# RZT2H register map
Vendor: Renesas Electronics Corporation; Series: RZT; File version: 1.00.00
CPU: other r0p0, little endian, MPU, no FPU, VTOR, 4 interrupt priority bits, 624 interrupts
Registers are 32-bit, read-write, reset 0x0 unless marked. A register's access mark holds for its fields unless they carry their own. Offsets are from the block's base; [hi:lo] are bit positions; {n}, {i} and the like mark numbered series.

## DDRSS
Base 0x80300000
0x00 DDR_MEMC_DENALI_CTL_00
  [0] start
0x100 DDR_MEMC_DENALI_CTL_64
  [13:8] BSTLEN
0x19C DDR_MEMC_DENALI_CTL_103
  [0] PWRUP_SREFRESH_EXIT
0x278 DDR_MEMC_DENALI_CTL_158
  [21:16] LPI_WAKEUP_EN
0x280 DDR_MEMC_DENALI_CTL_160
  [27:24] LP_AUTO_ENTRY_EN
0x29C DDR_MEMC_DENALI_CTL_167
  [8] PCPCS_PD_EN
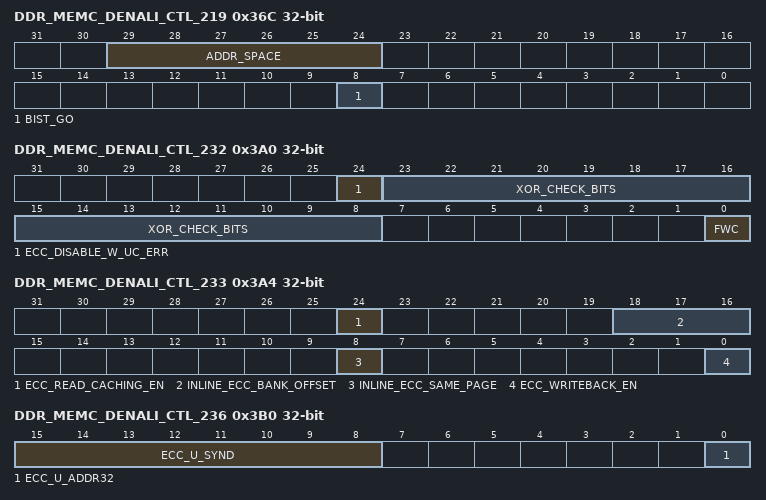
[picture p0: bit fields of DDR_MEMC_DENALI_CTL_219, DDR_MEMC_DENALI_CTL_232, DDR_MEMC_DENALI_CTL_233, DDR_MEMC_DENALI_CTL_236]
0x36C DDR_MEMC_DENALI_CTL_219
  [29:24] ADDR_SPACE, [8] BIST_GO
0x370 DDR_MEMC_DENALI_CTL_220
  [0] BIST_DATA_CHECK
0x374 DDR_MEMC_DENALI_CTL_221
  [31:0] BIST_START_ADDRESS
0x378 DDR_MEMC_DENALI_CTL_222
  [0] BIST_START_ADDRESS32
0x384 DDR_MEMC_DENALI_CTL_225
  [2:0] BIST_TEST_MODE
{0x0+4i} DDR_MEMC_DENALI_CTL_{i} (i=226..229)
  [31:0] BIST_DATA_PATTERN{i-226}
0x39C DDR_MEMC_DENALI_CTL_231
  [25:24] ECC_ENABLE
0x3A0 DDR_MEMC_DENALI_CTL_232
  [24] ECC_DISABLE_W_UC_ERR, [23:8] XOR_CHECK_BITS, [0] FWC
0x3A4 DDR_MEMC_DENALI_CTL_233
  [24] ECC_READ_CACHING_EN, [18:16] INLINE_ECC_BANK_OFFSET, [8] INLINE_ECC_SAME_PAGE, [0] ECC_WRITEBACK_EN
0x3A8 DDR_MEMC_DENALI_CTL_234
  [0] ECC_WRITE_COMBINING_EN
0x3AC DDR_MEMC_DENALI_CTL_235 ro
  [31:0] ECC_U_ADDR
0x3B0 DDR_MEMC_DENALI_CTL_236 ro
  [15:8] ECC_U_SYND, [0] ECC_U_ADDR32
0x3B4 DDR_MEMC_DENALI_CTL_237 ro
  [31:0] ECC_U_DATA0
0x3B8 DDR_MEMC_DENALI_CTL_238 ro
  [31:0] ECC_U_DATA1
0x3BC DDR_MEMC_DENALI_CTL_239 ro
  [31:0] ECC_C_ADDR
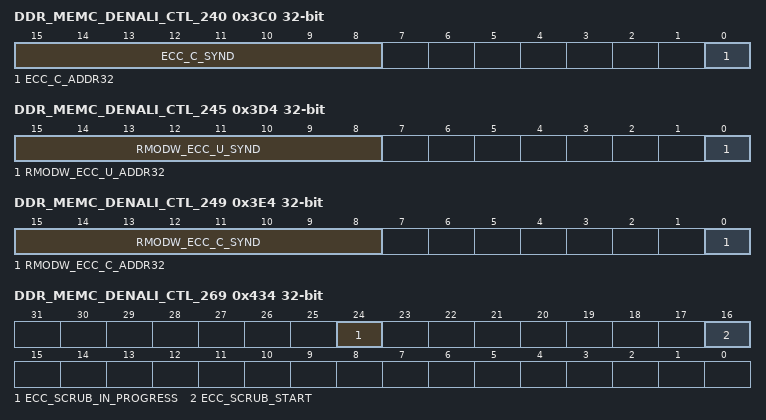
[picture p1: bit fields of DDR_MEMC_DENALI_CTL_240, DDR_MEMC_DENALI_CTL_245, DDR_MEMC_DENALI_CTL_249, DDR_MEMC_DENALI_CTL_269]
0x3C0 DDR_MEMC_DENALI_CTL_240 ro
  [15:8] ECC_C_SYND, [0] ECC_C_ADDR32
0x3C4 DDR_MEMC_DENALI_CTL_241 ro
  [31:0] ECC_C_DATA0
0x3C8 DDR_MEMC_DENALI_CTL_242 ro
  [31:0] ECC_C_DATA1
0x3D0 DDR_MEMC_DENALI_CTL_244 ro
  [31:0] RMODW_ECC_U_ADDR
0x3D4 DDR_MEMC_DENALI_CTL_245 ro
  [15:8] RMODW_ECC_U_SYND, [0] RMODW_ECC_U_ADDR32
0x3D8 DDR_MEMC_DENALI_CTL_246 ro
  [31:0] RMODW_ECC_U_DATA0
0x3DC DDR_MEMC_DENALI_CTL_247 ro
  [31:0] RMODW_ECC_U_DATA1
0x3E0 DDR_MEMC_DENALI_CTL_248 ro
  [31:0] RMODW_ECC_C_ADDR
0x3E4 DDR_MEMC_DENALI_CTL_249 ro
  [15:8] RMODW_ECC_C_SYND, [0] RMODW_ECC_C_ADDR32
0x3E8 DDR_MEMC_DENALI_CTL_250 ro
  [31:0] RMODW_ECC_C_DATA0
0x3EC DDR_MEMC_DENALI_CTL_251 ro
  [31:0] RMODW_ECC_C_DATA1
0x434 DDR_MEMC_DENALI_CTL_269
  [24] ECC_SCRUB_IN_PROGRESS ro, [16] ECC_SCRUB_START wo
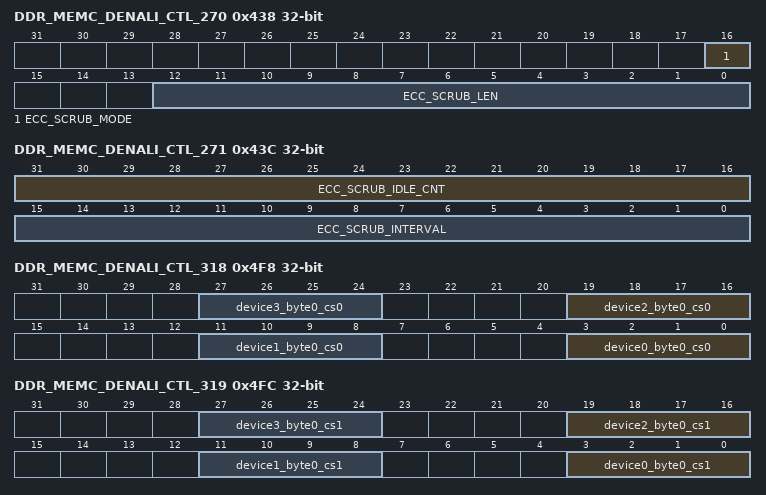
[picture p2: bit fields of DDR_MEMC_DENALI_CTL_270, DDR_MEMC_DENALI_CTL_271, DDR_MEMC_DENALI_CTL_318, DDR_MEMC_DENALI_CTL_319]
0x438 DDR_MEMC_DENALI_CTL_270
  [16] ECC_SCRUB_MODE, [12:0] ECC_SCRUB_LEN
0x43C DDR_MEMC_DENALI_CTL_271
  [31:16] ECC_SCRUB_IDLE_CNT, [15:0] ECC_SCRUB_INTERVAL
0x440 DDR_MEMC_DENALI_CTL_272
  [31:0] ECC_SCRUB_START_ADDR
0x444 DDR_MEMC_DENALI_CTL_273
  [0] ECC_SCRUB_START_ADDR32
0x448 DDR_MEMC_DENALI_CTL_274
  [31:0] ECC_SCRUB_END_ADDR
0x44C DDR_MEMC_DENALI_CTL_275
  [0] ECC_SCRUB_END_ADDR32
0x4C0 DDR_MEMC_DENALI_CTL_304
  [31:16] CS_VAL_UPPER_0
0x4C8 DDR_MEMC_DENALI_CTL_306
  [31:16] CS_VAL_UPPER_1
0x4E0 DDR_MEMC_DENALI_CTL_312
  [25:24] CS_MAP
0x4E4 DDR_MEMC_DENALI_CTL_313
  [0] MEM_DP_REDUCTION
0x4F8 DDR_MEMC_DENALI_CTL_318
  [8n+3:8n] device{n}_byte0_cs0 (n=0..3)
0x4FC DDR_MEMC_DENALI_CTL_319
  [8n+3:8n] device{n}_byte0_cs1 (n=0..3)
0x518 DDR_MEMC_DENALI_CTL_326 ro
  [31:0] INT_STATUS_MASTER
0x51C DDR_MEMC_DENALI_CTL_327 wo
  [31:0] INT_MASK_MASTER
0x520 DDR_MEMC_DENALI_CTL_328 ro
  [31:0] INT_STATUS_TIMEOUT
0x524 DDR_MEMC_DENALI_CTL_329 ro
  [31:0] INT_STATUS_ECC
0x528 DDR_MEMC_DENALI_CTL_330 ro
  [15:0] INT_STATUS_LOWPOWER
0x530 DDR_MEMC_DENALI_CTL_332 ro
  [31:0] INT_STATUS_TRAINING
0x534 DDR_MEMC_DENALI_CTL_333 ro
  [31:0] INT_STATUS_USERIF
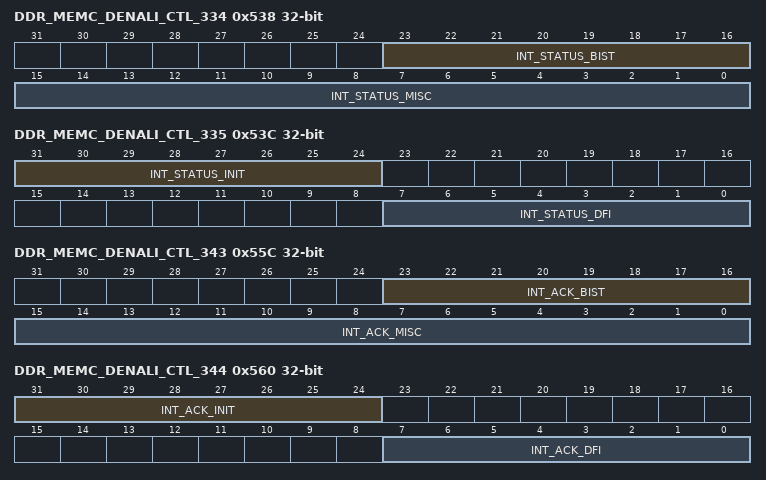
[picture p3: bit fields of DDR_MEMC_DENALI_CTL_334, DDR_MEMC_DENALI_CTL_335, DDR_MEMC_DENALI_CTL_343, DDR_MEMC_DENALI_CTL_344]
0x538 DDR_MEMC_DENALI_CTL_334 ro
  [23:16] INT_STATUS_BIST, [15:0] INT_STATUS_MISC
0x53C DDR_MEMC_DENALI_CTL_335 ro
  [31:24] INT_STATUS_INIT, [7:0] INT_STATUS_DFI
0x540 DDR_MEMC_DENALI_CTL_336 ro
  [7:0] INT_STATUS_MODE
0x544 DDR_MEMC_DENALI_CTL_337 wo
  [31:0] INT_ACK_TIMEOUT
0x548 DDR_MEMC_DENALI_CTL_338 wo
  [31:0] INT_ACK_ECC
0x54C DDR_MEMC_DENALI_CTL_339 wo
  [15:0] INT_ACK_LOWPOWER
0x554 DDR_MEMC_DENALI_CTL_341 wo
  [31:0] INT_ACK_TRAINING
0x558 DDR_MEMC_DENALI_CTL_342 wo
  [31:0] INT_ACK_USERIF
0x55C DDR_MEMC_DENALI_CTL_343 wo
  [23:16] INT_ACK_BIST, [15:0] INT_ACK_MISC
0x560 DDR_MEMC_DENALI_CTL_344 wo
  [31:24] INT_ACK_INIT, [7:0] INT_ACK_DFI
0x564 DDR_MEMC_DENALI_CTL_345 wo
  [7:0] INT_ACK_MODE
0x568 DDR_MEMC_DENALI_CTL_346
  [31:0] INT_MASK_TIMEOUT
0x56C DDR_MEMC_DENALI_CTL_347
  [31:0] INT_MASK_ECC
0x570 DDR_MEMC_DENALI_CTL_348
  [15:0] INT_MASK_LOWPOWER
0x578 DDR_MEMC_DENALI_CTL_350
  [31:0] INT_MASK_TRAINING
0x57C DDR_MEMC_DENALI_CTL_351
  [31:0] INT_MASK_USERIF
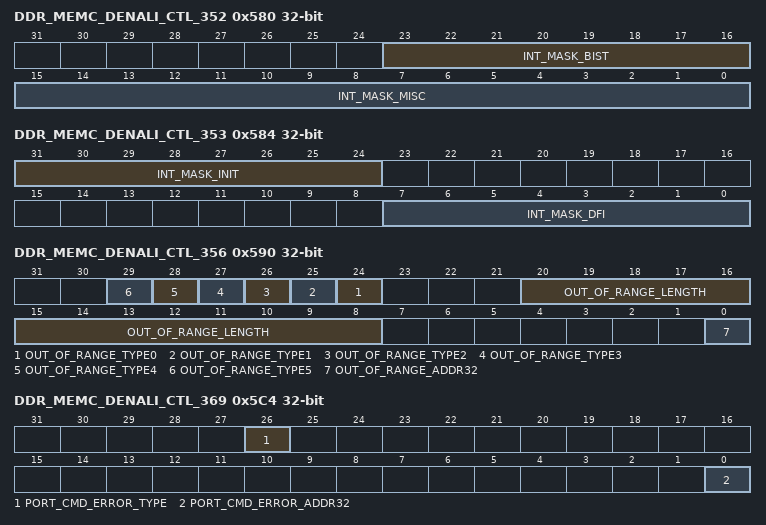
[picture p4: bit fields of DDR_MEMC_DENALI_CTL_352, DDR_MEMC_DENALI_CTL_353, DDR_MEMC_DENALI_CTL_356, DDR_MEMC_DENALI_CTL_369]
0x580 DDR_MEMC_DENALI_CTL_352
  [23:16] INT_MASK_BIST, [15:0] INT_MASK_MISC
0x584 DDR_MEMC_DENALI_CTL_353
  [31:24] INT_MASK_INIT, [7:0] INT_MASK_DFI
0x588 DDR_MEMC_DENALI_CTL_354
  [7:0] INT_MASK_MODE
0x58C DDR_MEMC_DENALI_CTL_355 ro
  [31:0] OUT_OF_RANGE_ADDR
0x590 DDR_MEMC_DENALI_CTL_356 ro
  [n+24] OUT_OF_RANGE_TYPE{n} (n=0..5), [20:8] OUT_OF_RANGE_LENGTH, [0] OUT_OF_RANGE_ADDR32
0x5C0 DDR_MEMC_DENALI_CTL_368 ro
  [31:0] PORT_CMD_ERROR_ADDR
0x5C4 DDR_MEMC_DENALI_CTL_369 ro
  [26] PORT_CMD_ERROR_TYPE, [0] PORT_CMD_ERROR_ADDR32
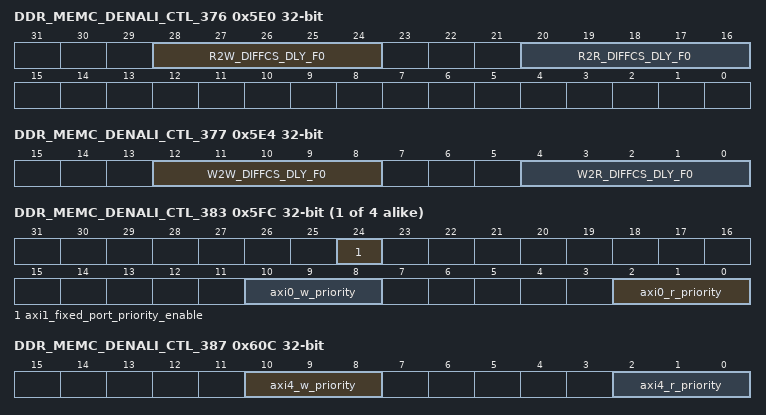
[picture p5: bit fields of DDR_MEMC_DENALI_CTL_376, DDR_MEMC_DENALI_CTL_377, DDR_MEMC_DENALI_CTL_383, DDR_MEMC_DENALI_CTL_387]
0x5E0 DDR_MEMC_DENALI_CTL_376
  [28:24] R2W_DIFFCS_DLY_F0, [20:16] R2R_DIFFCS_DLY_F0
0x5E4 DDR_MEMC_DENALI_CTL_377
  [12:8] W2W_DIFFCS_DLY_F0, [4:0] W2R_DIFFCS_DLY_F0
0x5F8 DDR_MEMC_DENALI_CTL_382
  [24] axi0_fixed_port_priority_enable
{0x0+4i} DDR_MEMC_DENALI_CTL_{i} (i=383..386)
  [24] axi{i-382}_fixed_port_priority_enable, [10:8] axi{i-383}_w_priority, [2:0] axi{i-383}_r_priority
0x60C DDR_MEMC_DENALI_CTL_387
  [10:8] axi4_w_priority, [2:0] axi4_r_priority
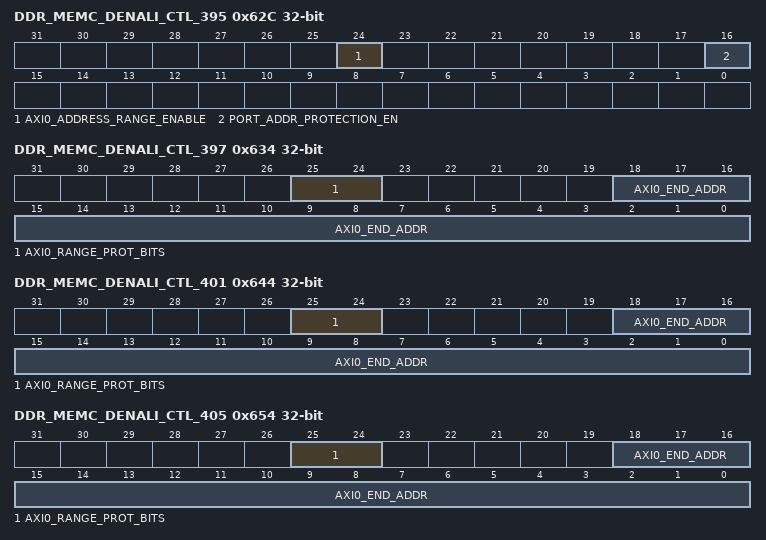
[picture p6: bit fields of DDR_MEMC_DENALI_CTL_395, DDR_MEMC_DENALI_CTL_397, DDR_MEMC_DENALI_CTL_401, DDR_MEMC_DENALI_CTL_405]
0x62C DDR_MEMC_DENALI_CTL_395
  [24] AXI0_ADDRESS_RANGE_ENABLE, [16] PORT_ADDR_PROTECTION_EN
0x630 DDR_MEMC_DENALI_CTL_396
  [18:0] AXI0_START_ADDR
0x634 DDR_MEMC_DENALI_CTL_397
  [25:24] AXI0_RANGE_PROT_BITS, [18:0] AXI0_END_ADDR
0x640 DDR_MEMC_DENALI_CTL_400
  [18:0] AXI0_START_ADDR
0x644 DDR_MEMC_DENALI_CTL_401
  [25:24] AXI0_RANGE_PROT_BITS, [18:0] AXI0_END_ADDR
0x650 DDR_MEMC_DENALI_CTL_404
  [18:0] AXI0_START_ADDR
0x654 DDR_MEMC_DENALI_CTL_405
  [25:24] AXI0_RANGE_PROT_BITS, [18:0] AXI0_END_ADDR
0x660 DDR_MEMC_DENALI_CTL_408
  [18:0] AXI0_START_ADDR
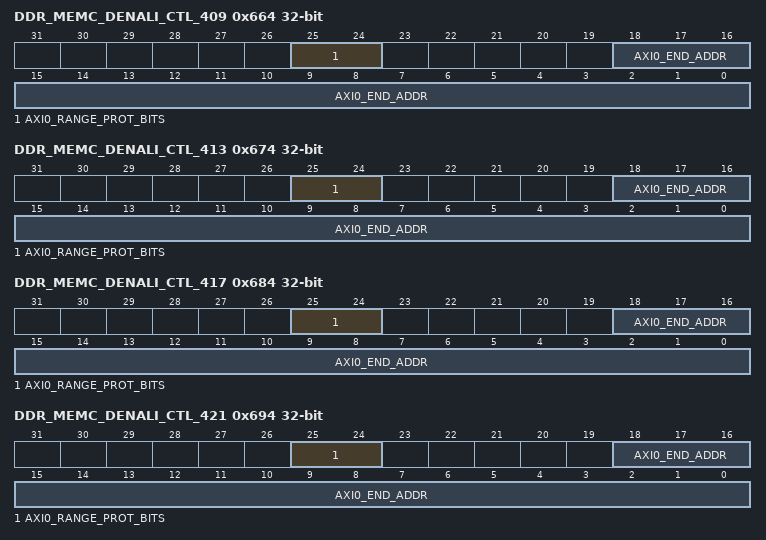
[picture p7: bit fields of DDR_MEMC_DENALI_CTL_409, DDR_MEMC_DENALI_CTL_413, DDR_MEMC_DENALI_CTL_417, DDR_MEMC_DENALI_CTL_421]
0x664 DDR_MEMC_DENALI_CTL_409
  [25:24] AXI0_RANGE_PROT_BITS, [18:0] AXI0_END_ADDR
0x670 DDR_MEMC_DENALI_CTL_412
  [18:0] AXI0_START_ADDR
0x674 DDR_MEMC_DENALI_CTL_413
  [25:24] AXI0_RANGE_PROT_BITS, [18:0] AXI0_END_ADDR
0x680 DDR_MEMC_DENALI_CTL_416
  [18:0] AXI0_START_ADDR
0x684 DDR_MEMC_DENALI_CTL_417
  [25:24] AXI0_RANGE_PROT_BITS, [18:0] AXI0_END_ADDR
0x690 DDR_MEMC_DENALI_CTL_420
  [18:0] AXI0_START_ADDR
0x694 DDR_MEMC_DENALI_CTL_421
  [25:24] AXI0_RANGE_PROT_BITS, [18:0] AXI0_END_ADDR
0x6A0 DDR_MEMC_DENALI_CTL_424
  [18:0] AXI0_START_ADDR
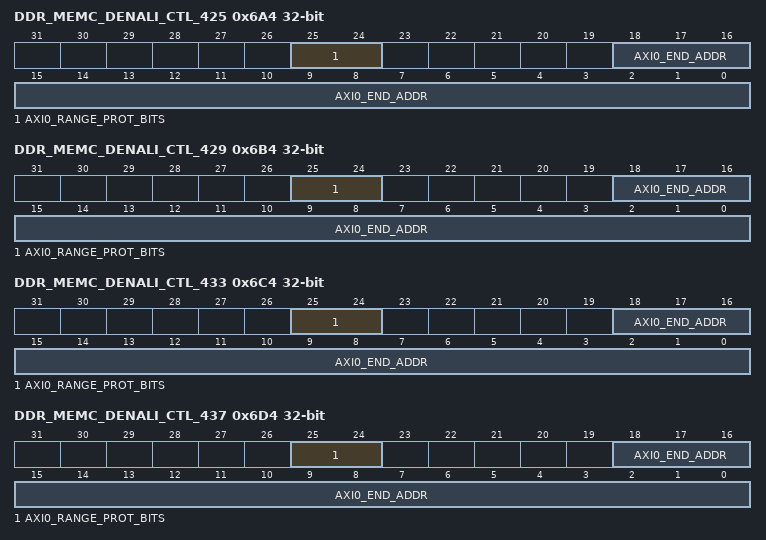
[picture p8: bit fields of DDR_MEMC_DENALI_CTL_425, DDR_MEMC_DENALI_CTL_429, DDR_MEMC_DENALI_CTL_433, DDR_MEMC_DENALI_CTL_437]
0x6A4 DDR_MEMC_DENALI_CTL_425
  [25:24] AXI0_RANGE_PROT_BITS, [18:0] AXI0_END_ADDR
0x6B0 DDR_MEMC_DENALI_CTL_428
  [18:0] AXI0_START_ADDR
0x6B4 DDR_MEMC_DENALI_CTL_429
  [25:24] AXI0_RANGE_PROT_BITS, [18:0] AXI0_END_ADDR
0x6C0 DDR_MEMC_DENALI_CTL_432
  [18:0] AXI0_START_ADDR
0x6C4 DDR_MEMC_DENALI_CTL_433
  [25:24] AXI0_RANGE_PROT_BITS, [18:0] AXI0_END_ADDR
0x6D0 DDR_MEMC_DENALI_CTL_436
  [18:0] AXI0_START_ADDR
0x6D4 DDR_MEMC_DENALI_CTL_437
  [25:24] AXI0_RANGE_PROT_BITS, [18:0] AXI0_END_ADDR
0x6E0 DDR_MEMC_DENALI_CTL_440
  [18:0] AXI0_START_ADDR
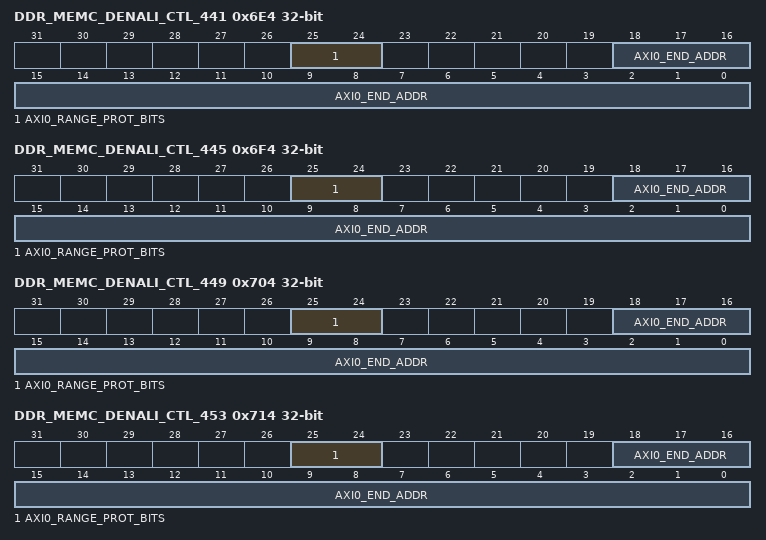
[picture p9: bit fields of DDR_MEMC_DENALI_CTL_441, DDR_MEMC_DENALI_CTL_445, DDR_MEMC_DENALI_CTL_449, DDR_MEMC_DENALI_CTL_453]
0x6E4 DDR_MEMC_DENALI_CTL_441
  [25:24] AXI0_RANGE_PROT_BITS, [18:0] AXI0_END_ADDR
0x6F0 DDR_MEMC_DENALI_CTL_444
  [18:0] AXI0_START_ADDR
0x6F4 DDR_MEMC_DENALI_CTL_445
  [25:24] AXI0_RANGE_PROT_BITS, [18:0] AXI0_END_ADDR
0x700 DDR_MEMC_DENALI_CTL_448
  [18:0] AXI0_START_ADDR
0x704 DDR_MEMC_DENALI_CTL_449
  [25:24] AXI0_RANGE_PROT_BITS, [18:0] AXI0_END_ADDR
0x710 DDR_MEMC_DENALI_CTL_452
  [18:0] AXI0_START_ADDR
0x714 DDR_MEMC_DENALI_CTL_453
  [25:24] AXI0_RANGE_PROT_BITS, [18:0] AXI0_END_ADDR
0x720 DDR_MEMC_DENALI_CTL_456
  [18:0] AXI0_START_ADDR
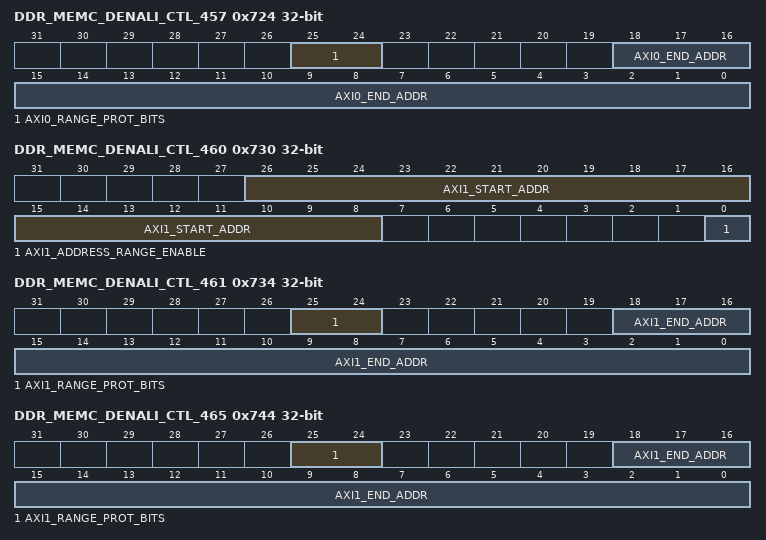
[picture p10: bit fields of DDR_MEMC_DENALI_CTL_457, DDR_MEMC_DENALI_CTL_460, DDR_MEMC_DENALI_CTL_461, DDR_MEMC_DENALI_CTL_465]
0x724 DDR_MEMC_DENALI_CTL_457
  [25:24] AXI0_RANGE_PROT_BITS, [18:0] AXI0_END_ADDR
0x730 DDR_MEMC_DENALI_CTL_460
  [26:8] AXI1_START_ADDR, [0] AXI1_ADDRESS_RANGE_ENABLE
0x734 DDR_MEMC_DENALI_CTL_461
  [25:24] AXI1_RANGE_PROT_BITS, [18:0] AXI1_END_ADDR
0x740 DDR_MEMC_DENALI_CTL_464
  [18:0] AXI1_START_ADDR
0x744 DDR_MEMC_DENALI_CTL_465
  [25:24] AXI1_RANGE_PROT_BITS, [18:0] AXI1_END_ADDR
0x750 DDR_MEMC_DENALI_CTL_468
  [18:0] AXI1_START_ADDR
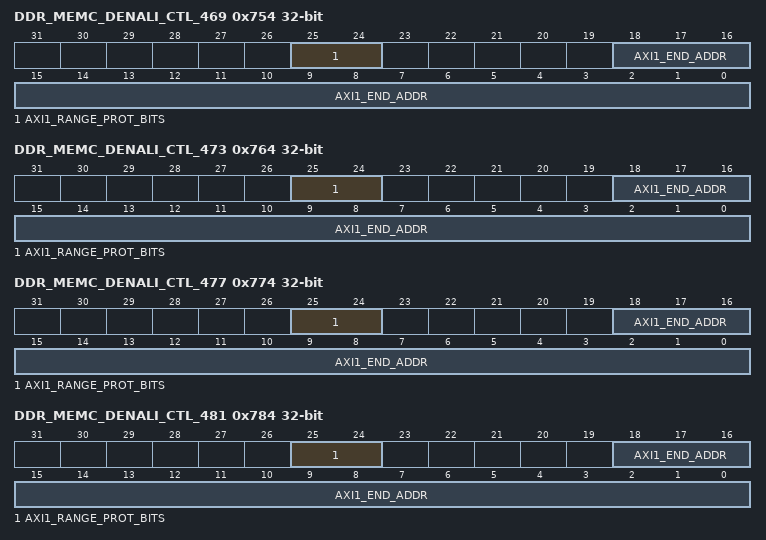
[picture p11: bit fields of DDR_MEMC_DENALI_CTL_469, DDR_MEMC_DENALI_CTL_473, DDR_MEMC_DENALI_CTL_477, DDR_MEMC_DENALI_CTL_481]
0x754 DDR_MEMC_DENALI_CTL_469
  [25:24] AXI1_RANGE_PROT_BITS, [18:0] AXI1_END_ADDR
0x760 DDR_MEMC_DENALI_CTL_472
  [18:0] AXI1_START_ADDR
0x764 DDR_MEMC_DENALI_CTL_473
  [25:24] AXI1_RANGE_PROT_BITS, [18:0] AXI1_END_ADDR
0x770 DDR_MEMC_DENALI_CTL_476
  [18:0] AXI1_START_ADDR
0x774 DDR_MEMC_DENALI_CTL_477
  [25:24] AXI1_RANGE_PROT_BITS, [18:0] AXI1_END_ADDR
0x780 DDR_MEMC_DENALI_CTL_480
  [18:0] AXI1_START_ADDR
0x784 DDR_MEMC_DENALI_CTL_481
  [25:24] AXI1_RANGE_PROT_BITS, [18:0] AXI1_END_ADDR
0x790 DDR_MEMC_DENALI_CTL_484
  [18:0] AXI1_START_ADDR
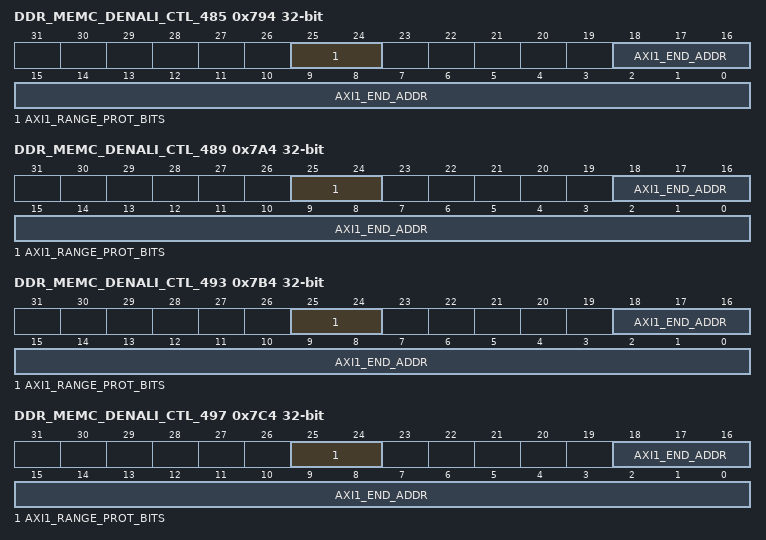
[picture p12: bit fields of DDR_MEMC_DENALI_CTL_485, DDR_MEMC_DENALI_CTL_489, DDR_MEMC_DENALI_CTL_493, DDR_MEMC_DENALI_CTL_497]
0x794 DDR_MEMC_DENALI_CTL_485
  [25:24] AXI1_RANGE_PROT_BITS, [18:0] AXI1_END_ADDR
0x7A0 DDR_MEMC_DENALI_CTL_488
  [18:0] AXI1_START_ADDR
0x7A4 DDR_MEMC_DENALI_CTL_489
  [25:24] AXI1_RANGE_PROT_BITS, [18:0] AXI1_END_ADDR
0x7B0 DDR_MEMC_DENALI_CTL_492
  [18:0] AXI1_START_ADDR
0x7B4 DDR_MEMC_DENALI_CTL_493
  [25:24] AXI1_RANGE_PROT_BITS, [18:0] AXI1_END_ADDR
0x7C0 DDR_MEMC_DENALI_CTL_496
  [18:0] AXI1_START_ADDR
0x7C4 DDR_MEMC_DENALI_CTL_497
  [25:24] AXI1_RANGE_PROT_BITS, [18:0] AXI1_END_ADDR
0x7D0 DDR_MEMC_DENALI_CTL_500
  [18:0] AXI1_START_ADDR
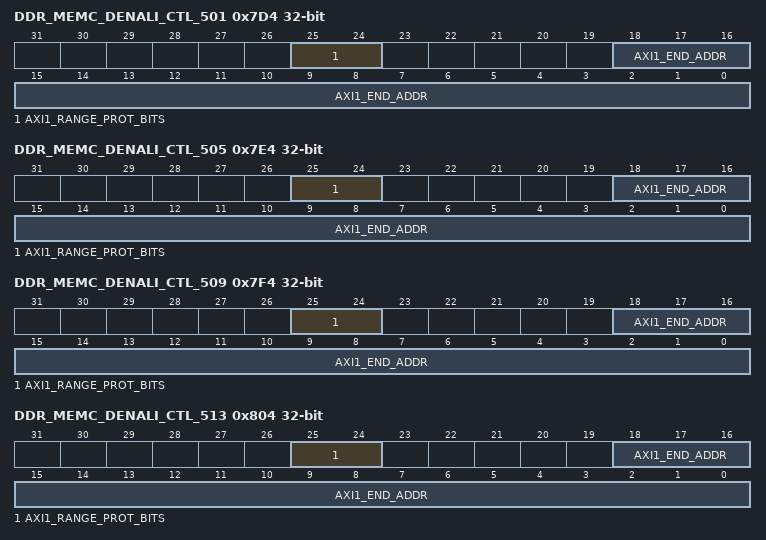
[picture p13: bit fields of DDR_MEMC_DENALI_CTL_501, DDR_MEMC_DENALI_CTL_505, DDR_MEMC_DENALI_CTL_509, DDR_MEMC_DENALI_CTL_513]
0x7D4 DDR_MEMC_DENALI_CTL_501
  [25:24] AXI1_RANGE_PROT_BITS, [18:0] AXI1_END_ADDR
0x7E0 DDR_MEMC_DENALI_CTL_504
  [18:0] AXI1_START_ADDR
0x7E4 DDR_MEMC_DENALI_CTL_505
  [25:24] AXI1_RANGE_PROT_BITS, [18:0] AXI1_END_ADDR
0x7F0 DDR_MEMC_DENALI_CTL_508
  [18:0] AXI1_START_ADDR
0x7F4 DDR_MEMC_DENALI_CTL_509
  [25:24] AXI1_RANGE_PROT_BITS, [18:0] AXI1_END_ADDR
0x800 DDR_MEMC_DENALI_CTL_512
  [18:0] AXI1_START_ADDR
0x804 DDR_MEMC_DENALI_CTL_513
  [25:24] AXI1_RANGE_PROT_BITS, [18:0] AXI1_END_ADDR
0x810 DDR_MEMC_DENALI_CTL_516
  [18:0] AXI1_START_ADDR
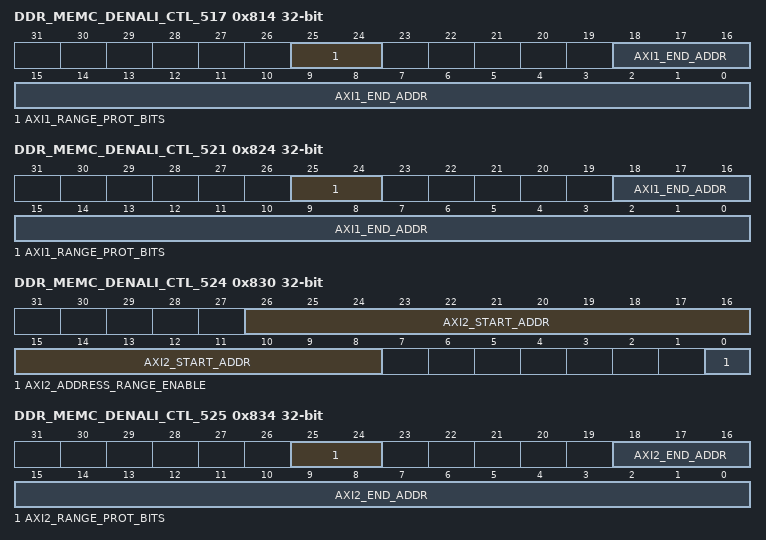
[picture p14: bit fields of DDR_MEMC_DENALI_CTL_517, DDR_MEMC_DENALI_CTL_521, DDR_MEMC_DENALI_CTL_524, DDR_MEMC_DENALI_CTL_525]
0x814 DDR_MEMC_DENALI_CTL_517
  [25:24] AXI1_RANGE_PROT_BITS, [18:0] AXI1_END_ADDR
0x820 DDR_MEMC_DENALI_CTL_520
  [18:0] AXI1_START_ADDR
0x824 DDR_MEMC_DENALI_CTL_521
  [25:24] AXI1_RANGE_PROT_BITS, [18:0] AXI1_END_ADDR
0x830 DDR_MEMC_DENALI_CTL_524
  [26:8] AXI2_START_ADDR, [0] AXI2_ADDRESS_RANGE_ENABLE
0x834 DDR_MEMC_DENALI_CTL_525
  [25:24] AXI2_RANGE_PROT_BITS, [18:0] AXI2_END_ADDR
0x840 DDR_MEMC_DENALI_CTL_528
  [18:0] AXI2_START_ADDR
0x844 DDR_MEMC_DENALI_CTL_529
  [25:24] AXI2_RANGE_PROT_BITS, [18:0] AXI2_END_ADDR
0x850 DDR_MEMC_DENALI_CTL_532
  [18:0] AXI2_START_ADDR
0x854 DDR_MEMC_DENALI_CTL_533
  [25:24] AXI2_RANGE_PROT_BITS, [18:0] AXI2_END_ADDR
0x860 DDR_MEMC_DENALI_CTL_536
  [18:0] AXI2_START_ADDR
0x864 DDR_MEMC_DENALI_CTL_537
  [25:24] AXI2_RANGE_PROT_BITS, [18:0] AXI2_END_ADDR
0x870 DDR_MEMC_DENALI_CTL_540
  [18:0] AXI2_START_ADDR
0x874 DDR_MEMC_DENALI_CTL_541
  [25:24] AXI2_RANGE_PROT_BITS, [18:0] AXI2_END_ADDR
0x880 DDR_MEMC_DENALI_CTL_544
  [18:0] AXI2_START_ADDR
0x884 DDR_MEMC_DENALI_CTL_545
  [25:24] AXI2_RANGE_PROT_BITS, [18:0] AXI2_END_ADDR
0x890 DDR_MEMC_DENALI_CTL_548
  [18:0] AXI2_START_ADDR
0x894 DDR_MEMC_DENALI_CTL_549
  [25:24] AXI2_RANGE_PROT_BITS, [18:0] AXI2_END_ADDR
0x8A0 DDR_MEMC_DENALI_CTL_552
  [18:0] AXI2_START_ADDR
0x8A4 DDR_MEMC_DENALI_CTL_553
  [25:24] AXI2_RANGE_PROT_BITS, [18:0] AXI2_END_ADDR
0x8B0 DDR_MEMC_DENALI_CTL_556
  [18:0] AXI2_START_ADDR
0x8B4 DDR_MEMC_DENALI_CTL_557
  [25:24] AXI2_RANGE_PROT_BITS, [18:0] AXI2_END_ADDR
0x8C0 DDR_MEMC_DENALI_CTL_560
  [18:0] AXI2_START_ADDR
0x8C4 DDR_MEMC_DENALI_CTL_561
  [25:24] AXI2_RANGE_PROT_BITS, [18:0] AXI2_END_ADDR
0x8D0 DDR_MEMC_DENALI_CTL_564
  [18:0] AXI2_START_ADDR
0x8D4 DDR_MEMC_DENALI_CTL_565
  [25:24] AXI2_RANGE_PROT_BITS, [18:0] AXI2_END_ADDR
0x8E0 DDR_MEMC_DENALI_CTL_568
  [18:0] AXI2_START_ADDR
0x8E4 DDR_MEMC_DENALI_CTL_569
  [25:24] AXI2_RANGE_PROT_BITS, [18:0] AXI2_END_ADDR
0x8F0 DDR_MEMC_DENALI_CTL_572
  [18:0] AXI2_START_ADDR
0x8F4 DDR_MEMC_DENALI_CTL_573
  [25:24] AXI2_RANGE_PROT_BITS, [18:0] AXI2_END_ADDR
0x900 DDR_MEMC_DENALI_CTL_576
  [18:0] AXI2_START_ADDR
0x904 DDR_MEMC_DENALI_CTL_577
  [25:24] AXI2_RANGE_PROT_BITS, [18:0] AXI2_END_ADDR
0x910 DDR_MEMC_DENALI_CTL_580
  [18:0] AXI2_START_ADDR
0x914 DDR_MEMC_DENALI_CTL_581
  [25:24] AXI2_RANGE_PROT_BITS, [18:0] AXI2_END_ADDR
0x920 DDR_MEMC_DENALI_CTL_584
  [18:0] AXI2_START_ADDR
0x924 DDR_MEMC_DENALI_CTL_585
  [25:24] AXI2_RANGE_PROT_BITS, [18:0] AXI2_END_ADDR
0x930 DDR_MEMC_DENALI_CTL_588
  [26:8] AXI3_START_ADDR, [0] AXI3_ADDRESS_RANGE_ENABLE
0x934 DDR_MEMC_DENALI_CTL_589
  [25:24] AXI3_RANGE_PROT_BITS, [18:0] AXI3_END_ADDR
0x940 DDR_MEMC_DENALI_CTL_592
  [18:0] AXI3_START_ADDR
0x944 DDR_MEMC_DENALI_CTL_593
  [25:24] AXI3_RANGE_PROT_BITS, [18:0] AXI3_END_ADDR
0x950 DDR_MEMC_DENALI_CTL_596
  [18:0] AXI3_START_ADDR
0x954 DDR_MEMC_DENALI_CTL_597
  [25:24] AXI3_RANGE_PROT_BITS, [18:0] AXI3_END_ADDR
0x960 DDR_MEMC_DENALI_CTL_600
  [18:0] AXI3_START_ADDR
0x964 DDR_MEMC_DENALI_CTL_601
  [25:24] AXI3_RANGE_PROT_BITS, [18:0] AXI3_END_ADDR
0x970 DDR_MEMC_DENALI_CTL_604
  [18:0] AXI3_START_ADDR
0x974 DDR_MEMC_DENALI_CTL_605
  [25:24] AXI3_RANGE_PROT_BITS, [18:0] AXI3_END_ADDR
0x980 DDR_MEMC_DENALI_CTL_608
  [18:0] AXI3_START_ADDR
0x984 DDR_MEMC_DENALI_CTL_609
  [25:24] AXI3_RANGE_PROT_BITS, [18:0] AXI3_END_ADDR
0x990 DDR_MEMC_DENALI_CTL_612
  [18:0] AXI3_START_ADDR
0x994 DDR_MEMC_DENALI_CTL_613
  [25:24] AXI3_RANGE_PROT_BITS, [18:0] AXI3_END_ADDR
0x9A0 DDR_MEMC_DENALI_CTL_616
  [18:0] AXI3_START_ADDR
0x9A4 DDR_MEMC_DENALI_CTL_617
  [25:24] AXI3_RANGE_PROT_BITS, [18:0] AXI3_END_ADDR
0x9B0 DDR_MEMC_DENALI_CTL_620
  [18:0] AXI3_START_ADDR
0x9B4 DDR_MEMC_DENALI_CTL_621
  [25:24] AXI3_RANGE_PROT_BITS, [18:0] AXI3_END_ADDR
0x9C0 DDR_MEMC_DENALI_CTL_624
  [18:0] AXI3_START_ADDR
0x9C4 DDR_MEMC_DENALI_CTL_625
  [25:24] AXI3_RANGE_PROT_BITS, [18:0] AXI3_END_ADDR
0x9D0 DDR_MEMC_DENALI_CTL_628
  [18:0] AXI3_START_ADDR
0x9D4 DDR_MEMC_DENALI_CTL_629
  [25:24] AXI3_RANGE_PROT_BITS, [18:0] AXI3_END_ADDR
0x9E0 DDR_MEMC_DENALI_CTL_632
  [18:0] AXI3_START_ADDR
0x9E4 DDR_MEMC_DENALI_CTL_633
  [25:24] AXI3_RANGE_PROT_BITS, [18:0] AXI3_END_ADDR
0x9F0 DDR_MEMC_DENALI_CTL_636
  [18:0] AXI3_START_ADDR
0x9F4 DDR_MEMC_DENALI_CTL_637
  [25:24] AXI3_RANGE_PROT_BITS, [18:0] AXI3_END_ADDR
0xA00 DDR_MEMC_DENALI_CTL_640
  [18:0] AXI3_START_ADDR
0xA04 DDR_MEMC_DENALI_CTL_641
  [25:24] AXI3_RANGE_PROT_BITS, [18:0] AXI3_END_ADDR
0xA10 DDR_MEMC_DENALI_CTL_644
  [18:0] AXI3_START_ADDR
0xA14 DDR_MEMC_DENALI_CTL_645
  [25:24] AXI3_RANGE_PROT_BITS, [18:0] AXI3_END_ADDR
0xA20 DDR_MEMC_DENALI_CTL_648
  [18:0] AXI3_START_ADDR
0xA24 DDR_MEMC_DENALI_CTL_649
  [25:24] AXI3_RANGE_PROT_BITS, [18:0] AXI3_END_ADDR
0xA30 DDR_MEMC_DENALI_CTL_652
  [26:8] AXI4_START_ADDR, [0] AXI4_ADDRESS_RANGE_ENABLE
0xA34 DDR_MEMC_DENALI_CTL_653
  [25:24] AXI4_RANGE_PROT_BITS, [18:0] AXI4_END_ADDR
0xA40 DDR_MEMC_DENALI_CTL_656
  [18:0] AXI4_START_ADDR
0xA44 DDR_MEMC_DENALI_CTL_657
  [25:24] AXI4_RANGE_PROT_BITS, [18:0] AXI4_END_ADDR
0xA50 DDR_MEMC_DENALI_CTL_660
  [18:0] AXI4_START_ADDR
0xA54 DDR_MEMC_DENALI_CTL_661
  [25:24] AXI4_RANGE_PROT_BITS, [18:0] AXI4_END_ADDR
0xA60 DDR_MEMC_DENALI_CTL_664
  [18:0] AXI4_START_ADDR
0xA64 DDR_MEMC_DENALI_CTL_665
  [25:24] AXI4_RANGE_PROT_BITS, [18:0] AXI4_END_ADDR
0xA70 DDR_MEMC_DENALI_CTL_668
  [18:0] AXI4_START_ADDR
0xA74 DDR_MEMC_DENALI_CTL_669
  [25:24] AXI4_RANGE_PROT_BITS, [18:0] AXI4_END_ADDR
0xA80 DDR_MEMC_DENALI_CTL_672
  [18:0] AXI4_START_ADDR
0xA84 DDR_MEMC_DENALI_CTL_673
  [25:24] AXI4_RANGE_PROT_BITS, [18:0] AXI4_END_ADDR
0xA90 DDR_MEMC_DENALI_CTL_676
  [18:0] AXI4_START_ADDR
0xA94 DDR_MEMC_DENALI_CTL_677
  [25:24] AXI4_RANGE_PROT_BITS, [18:0] AXI4_END_ADDR
0xAA0 DDR_MEMC_DENALI_CTL_680
  [18:0] AXI4_START_ADDR
0xAA4 DDR_MEMC_DENALI_CTL_681
  [25:24] AXI4_RANGE_PROT_BITS, [18:0] AXI4_END_ADDR
0xAB0 DDR_MEMC_DENALI_CTL_684
  [18:0] AXI4_START_ADDR
0xAB4 DDR_MEMC_DENALI_CTL_685
  [25:24] AXI4_RANGE_PROT_BITS, [18:0] AXI4_END_ADDR
0xAC0 DDR_MEMC_DENALI_CTL_688
  [18:0] AXI4_START_ADDR
0xAC4 DDR_MEMC_DENALI_CTL_689
  [25:24] AXI4_RANGE_PROT_BITS, [18:0] AXI4_END_ADDR
0xAD0 DDR_MEMC_DENALI_CTL_692
  [18:0] AXI4_START_ADDR
0xAD4 DDR_MEMC_DENALI_CTL_693
  [25:24] AXI4_RANGE_PROT_BITS, [18:0] AXI4_END_ADDR
0xAE0 DDR_MEMC_DENALI_CTL_696
  [18:0] AXI4_START_ADDR
0xAE4 DDR_MEMC_DENALI_CTL_697
  [25:24] AXI4_RANGE_PROT_BITS, [18:0] AXI4_END_ADDR
0xAF0 DDR_MEMC_DENALI_CTL_700
  [18:0] AXI4_START_ADDR
0xAF4 DDR_MEMC_DENALI_CTL_701
  [25:24] AXI4_RANGE_PROT_BITS, [18:0] AXI4_END_ADDR
0xB00 DDR_MEMC_DENALI_CTL_704
  [18:0] AXI4_START_ADDR
0xB04 DDR_MEMC_DENALI_CTL_705
  [25:24] AXI4_RANGE_PROT_BITS, [18:0] AXI4_END_ADDR
0xB10 DDR_MEMC_DENALI_CTL_708
  [18:0] AXI4_START_ADDR
0xB14 DDR_MEMC_DENALI_CTL_709
  [25:24] AXI4_RANGE_PROT_BITS, [18:0] AXI4_END_ADDR
0xB20 DDR_MEMC_DENALI_CTL_712
  [18:0] AXI4_START_ADDR
0xB24 DDR_MEMC_DENALI_CTL_713
  [25:24] AXI4_RANGE_PROT_BITS, [18:0] AXI4_END_ADDR
0xB30 DDR_MEMC_DENALI_CTL_716
  [27:24] axi0_priority0_relative_priority, [19:16] wrr_param_value_err ro, [9:8] weighted_round_robin_weight_sharing, [0] weighted_round_robin_latency_control
0xB34 DDR_MEMC_DENALI_CTL_717
  [8n-5:8n-8] axi0_priority{n}_relative_priority (n=1..4)
0xB38 DDR_MEMC_DENALI_CTL_718
  [26:24] axi0_port_ordering, [19:16] axi0_priority7_relative_priority, [11:8] axi0_priority6_relative_priority, [3:0] axi0_priority5_relative_priority
0xB3C DDR_MEMC_DENALI_CTL_719
  [27:24] axi1_priority1_relative_priority, [19:16] axi1_priority0_relative_priority, [9:0] axi0_priority_relax
0xB40 DDR_MEMC_DENALI_CTL_720
  [8n-13:8n-16] axi1_priority{n}_relative_priority (n=2..5)
0xB44 DDR_MEMC_DENALI_CTL_721
  [18:16] axi1_port_ordering, [11:8] axi1_priority7_relative_priority, [3:0] axi1_priority6_relative_priority
0xB48 DDR_MEMC_DENALI_CTL_722
  [27:24] axi2_priority1_relative_priority, [19:16] axi2_priority0_relative_priority, [9:0] axi1_priority_relax
0xB4C DDR_MEMC_DENALI_CTL_723
  [8n-13:8n-16] axi2_priority{n}_relative_priority (n=2..5)
0xB50 DDR_MEMC_DENALI_CTL_724
  [18:16] axi2_port_ordering, [11:8] axi2_priority7_relative_priority, [3:0] axi2_priority6_relative_priority
0xB54 DDR_MEMC_DENALI_CTL_725
  [27:24] axi3_priority1_relative_priority, [19:16] axi3_priority0_relative_priority, [9:0] axi2_priority_relax
0xB58 DDR_MEMC_DENALI_CTL_726
  [8n-13:8n-16] axi3_priority{n}_relative_priority (n=2..5)
0xB5C DDR_MEMC_DENALI_CTL_727
  [18:16] axi3_port_ordering, [11:8] axi3_priority7_relative_priority, [3:0] axi3_priority6_relative_priority
0xB60 DDR_MEMC_DENALI_CTL_728
  [27:24] axi4_priority1_relative_priority, [19:16] axi4_priority0_relative_priority, [9:0] axi3_priority_relax
0xB64 DDR_MEMC_DENALI_CTL_729
  [8n-13:8n-16] axi4_priority{n}_relative_priority (n=2..5)
0xB68 DDR_MEMC_DENALI_CTL_730
  [18:16] axi4_port_ordering, [11:8] axi4_priority7_relative_priority, [3:0] axi4_priority6_relative_priority
0xB6C DDR_MEMC_DENALI_CTL_731
  [9:0] axi4_priority_relax
0xB70 DDR_MEMC_DENALI_CTL_732
  [6:0] TDFI_PHY_RDLAT_F0
0xBE4 DDR_MEMC_DENALI_CTL_761
  [15:8] TDFI_WRDATA
0x2000 DDR_MEMC_MCAR_CTL
  [16] dfi_init_start, [8] set_axctl wo, [0] block_fm_norm_req
0x2004 DDR_MEMC_MCAR_MON
  [17] refresh_in_process ro, [16] q_almost_full ro, [4:0] port_busy ro
{0x2008+4i} DDR_MEMC_MCAR_AXCTL{i} (i=0..4)
  [8] axi{i}_awcobuf
